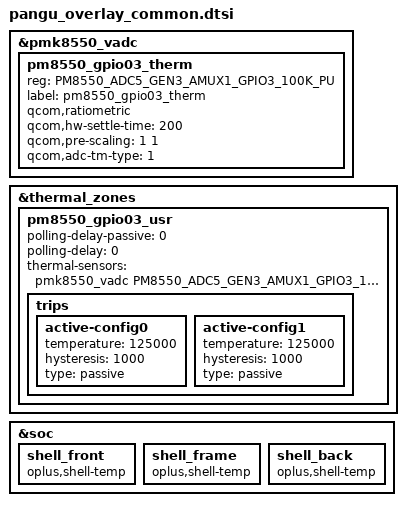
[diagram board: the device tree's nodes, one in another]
// Add the thermistors for shell-temp
&pmk8550_vadc {
	pm8550_gpio03_therm {
		reg = <PM8550_ADC5_GEN3_AMUX1_GPIO3_100K_PU>;
		label = "pm8550_gpio03_therm";
		qcom,ratiometric;
		qcom,hw-settle-time = <200>;
		qcom,pre-scaling = <1 1>;
		qcom,adc-tm-type = <1>;
	};
};

&thermal_zones {
	pm8550_gpio03_usr {
		polling-delay-passive = <0>;
		polling-delay = <0>;
		thermal-sensors = <&pmk8550_vadc PM8550_ADC5_GEN3_AMUX1_GPIO3_100K_PU>;
		trips {
			active-config0 {
				temperature = <125000>;
				hysteresis = <1000>;
				type = "passive";
			};
			active-config1 {
				temperature = <125000>;
				hysteresis = <1000>;
				type = "passive";
			};
		};
	};
};
&soc {
	//#ifdef OPLUS_FEATURE_THERMAL_HORAE
	shell_front {
		compatible = "oplus,shell-temp";
	};

	shell_frame {
		compatible = "oplus,shell-temp";
	};

	shell_back {
		compatible = "oplus,shell-temp";
	};
	//#endif /* OPLUS_FEATURE_THERMAL_HORAE */
};
